# NANO100AN_v1 register map
File version: 1.0
Registers are 32-bit, read-write, reset 0x0 unless marked. A register's access mark holds for its fields unless they carry their own. Offsets are from the block's base; [hi:lo] are bit positions; {n}, {i} and the like mark numbered series; 'fields as' and 'values as' point back to an identical list.

## DMA_GCR — VDMA Register Map
Base 0x50008F00
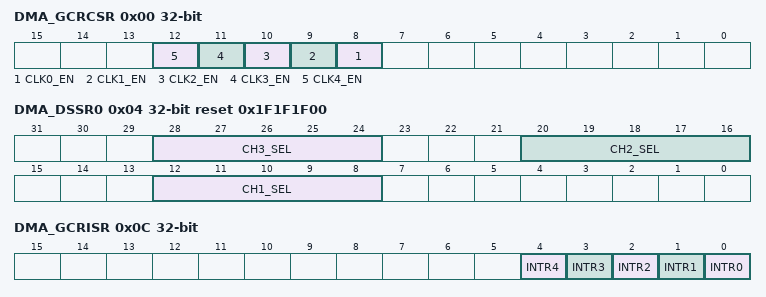
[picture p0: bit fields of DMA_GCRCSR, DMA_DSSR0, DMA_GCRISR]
0x00 DMA_GCRCSR — DMA Global Control Register
  [all] fields
    0=Disabled; 1=Enabled
  [n+8] CLK{n}_EN (n=0..4) — DMA Controller Channel {n} Clock Enable Control
0x04 DMA_DSSR0 reset 0x1F1F1F00 — DMA Service Selection Control Register 0
  [28:24] CH3_SEL — Channel 3 Selection. This filed defines which peripheral is connected to PDMA channel 3. User can configure the peripheral setting by CH3_SEL. The channel configuration is the same as CH1_SEL field. Please refer to the explanation of CH1_SEL.
  [20:16] CH2_SEL — Channel 2 Selection. This filed defines which peripheral is connected to PDMA channel 2. User can configure the peripheral setting by CH2_SEL. The channel configuration is the same as CH1_SEL field. Please refer to the explanation of CH1_SEL.
  [12:8] CH1_SEL — Channel 1 Selection. This filed defines which peripheral is connected to PDMA channel 1. User can configure the peripheral by setting CH1_SEL.
    0=Connect to SPI0_TX; 1=Connect to SPI1_TX; 2=Connect to UART0_TX; 3=Connect to UART1_TX; 4=Connect to USB_TX; 5=Connect to I2S_TX; 8=Connect to SPI2_TX; 9=Connect to TMR0 CH0; 10=Connect to TMR0 CH1; 11=Connect to TMR1 CH0; 12=Connect to TMR1 CH1; 16=Connect to SPI0_RX; 17=Connect to SPI1_RX; 18=Connect to UART0_RX; 19=Connect to UART1_RX; 20=Connect to USB_RX; 21=Connect to I2S_RX; 22=Connect to ADC; 24=Connect to SPI2_RX; 25=Connect to PWM0_CH0; 26=Connect to PWM0_CH2; 27=Connect to PWM1_CH0; 28=Connect to PWM1_CH2
0x08 DMA_DSSR1 reset 0x1F — DMA Service Selection Control Register 1
  [4:0] CH4_SEL — Channel 4 Selection. This filed defines which peripheral is connected to PDMA channel 4. User can configure the peripheral by setting CH4_SEL.
    values as DMA_DSSR0.CH1_SEL
0x0C DMA_GCRISR ro — DMA Global Interrupt Status Register
  [n] INTR{n} (n=0..4) — Interrupt Status Of Channel {n} (Read Only). This bit is the Interrupt status of DMA channel {n}.

## WDT — WDT Register Map
Base 0x40004000
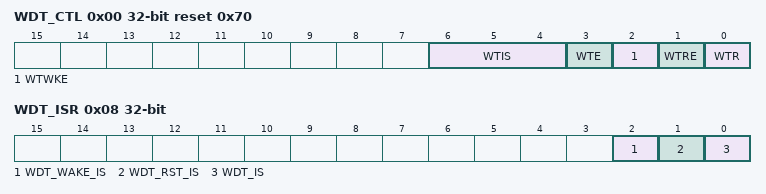
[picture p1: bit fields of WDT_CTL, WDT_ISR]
0x00 WDT_CTL reset 0x70 — Watchdog Timer Control Register
  [6:4] WTIS — Watchdog Timer Interval Selection (Write Protect). Please refer to open lock sequence to program it. The three bits select the time-out interval for the Watchdog timer. This count is free running counter. Please refer to Table 5.191 Watchdog Time-out Interval Selection
  [3] WTE — Watchdog Timer Enable Control (Write Protect). Please refer to open lock sequence to program it.
    0=Watchdog timer Disabled (this action will reset the internal counter); 1=Watchdog timer Enabled
  [2] WTWKE — Watchdog Timer Wake-Up Function Enable Control (Write Protect). Please refer to open lock sequence to program it.
    0=Watchdog timer Wake-up CPU function Disabled; 1=Wake-up function Enabled so that Watchdog timer time-out can wake up CPU from power-down mode
  [1] WTRE — Watchdog Timer Reset Function Enable Control (Write Protect). Please refer to open lock sequence to program it. Setting this bit will enable the Watchdog timer reset function.
    0=Watchdog timer reset function Disabled; 1=Watchdog timer reset function Enabled
  [0] WTR — Clear Watchdog Timer (Write Protect). Please refer to open lock sequence to program it. Set this bit will clear the Watchdog timer. Note: This bit will auto clear after few clock cycle
    0=No effect; 1=Reset the contents of the Watchdog timer
0x04 WDT_IER — Watchdog Timer Interrupt Enable Register
  [0] WDT_IE — Watchdog Timer Interrupt Enable Control
    0=Watchdog timer interrupt Disabled; 1=Watchdog timer interrupt Enabled
0x08 WDT_ISR — Watchdog Timer Interrupt Status Register
  [2] WDT_WAKE_IS ro — Watchdog Timer Wake-Up Status (Read Only). If Watchdog timer causes system to wake up from power-down mode, this bit will be set to high. It must be cleared by software with a write "1" to this bit. Note1: When system in power-down mode and watchdog time-out, hardware will set WDT_WAKE_IS and WDT_IS. Note2: After one engine clock., this bit can be cleared by writing "1" to it
    0=Watchdog timer does not cause system wake-up; 1=Wake system up from power-down mode by Watchdog time-out
  [1] WDT_RST_IS ro — Watchdog Timer Reset Status (Read Only). When the Watchdog timer initiates a reset, the hardware will set this bit. This flag can be read by software to determine the source of reset. Software is responsible to clear it manually by writing "1" to it. If WTRE is disabled, then the Watchdog timer has no effect on this bit. Note: This bit is read only, but can be cleared by writing "1" to it.
    0=Watchdog timer reset does not occur; 1=Watchdog timer reset occurs
  [0] WDT_IS ro — Watchdog Timer Interrupt Status (Read Only). If the Watchdog timer interrupt is enabled, then the hardware will set this bit to indicate that the Watchdog timer interrupt has occurred. If the Watchdog timer interrupt is not enabled, then this bit indicates that a time-out period has elapsed. Note: This bit is read only, but can be cleared by writing "1" to it.
    0=Watchdog timer interrupt does not occur; 1=Watchdog timer interrupt occurs
